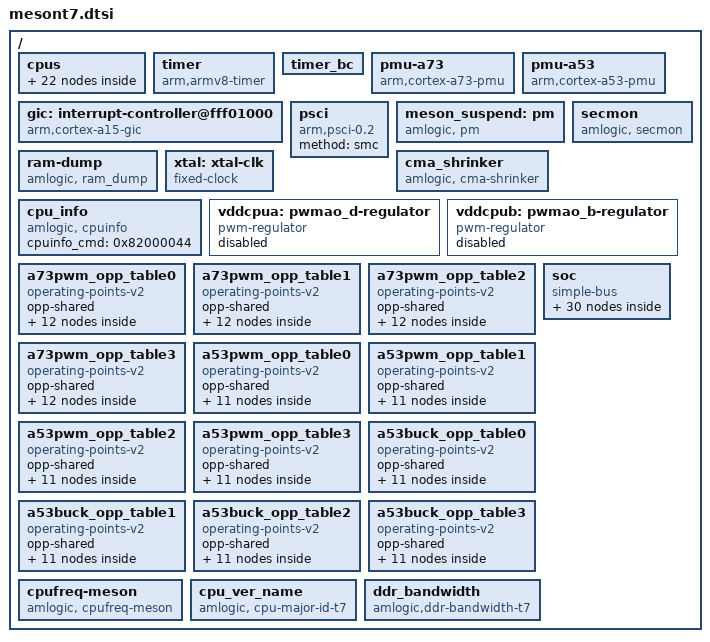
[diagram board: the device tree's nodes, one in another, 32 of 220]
// SPDX-License-Identifier: (GPL-2.0+ OR MIT)
/*
 * Copyright (c) 2019 Amlogic, Inc. All rights reserved.
 */

#include <dt-bindings/clock/amlogic,t7-clkc.h>
#include <dt-bindings/interrupt-controller/arm-gic.h>
#include <dt-bindings/gpio/gpio.h>
#include <dt-bindings/gpio/meson-t7-gpio.h>
#include <dt-bindings/pwm/meson.h>


/ {
	cpus:cpus {
		#address-cells = <2>;
		#size-cells = <0>;

		cpu-map {
			cluster0:cluster0 {
				core0 {
					cpu = <&CPU0>;
				};
				core1 {
					cpu = <&CPU1>;
				};
				core2 {
					cpu = <&CPU2>;
				};
				core3 {
					cpu = <&CPU3>;
				};
			};
			cluster1:cluster1 {
				core0 {
					cpu = <&CPU4>;
				};
				core1 {
					cpu = <&CPU5>;
				};
				core2 {
					cpu = <&CPU6>;
				};
				core3 {
					cpu = <&CPU7>;
				};
			};
		};

		CPU0:cpu@0 {
			device_type = "cpu";
			compatible = "arm,cortex-a73","arm,armv8";
			reg = <0x0 0x0>;
			enable-method = "psci";
			cpu-idle-states = <&CPU_SLEEP_0 &SYSTEM_SLEEP_0>;
//			#cooling-cells = <2>;
			clocks = <&clkc CLKID_A73_CLK>,
				<&clkc CLKID_A73_DYN_CLK>,
				<&clkc CLKID_SYS_PLL>;
			clock-names = "core_clk",
				"low_freq_clk_parent",
				"high_freq_clk_parent";
			voltage-tolerance = <0>;
			clock-latency = <50000>;
			capacity-dmips-mhz = <1024>;
			dynamic-power-coefficient = <550>;
			#cooling-cells = <2>;
		};

		CPU1:cpu@1 {
			device_type = "cpu";
			compatible = "arm,cortex-a73","arm,armv8";
			reg = <0x0 0x1>;
			enable-method = "psci";
			cpu-idle-states = <&CPU_SLEEP_0 &SYSTEM_SLEEP_0>;
//			#cooling-cells = <2>;
			clocks = <&clkc CLKID_A73_CLK>,
				<&clkc CLKID_A73_DYN_CLK>,
				<&clkc CLKID_SYS_PLL>;
			clock-names = "core_clk",
				"low_freq_clk_parent",
				"high_freq_clk_parent";
			voltage-tolerance = <0>;
			clock-latency = <50000>;
			capacity-dmips-mhz = <1024>;
			dynamic-power-coefficient = <550>;
			#cooling-cells = <2>;
		};

		CPU2:cpu@2 {
			device_type = "cpu";
			compatible = "arm,cortex-a73","arm,armv8";
			reg = <0x0 0x2>;
			enable-method = "psci";
			cpu-idle-states = <&CPU_SLEEP_0 &SYSTEM_SLEEP_0>;
//			#cooling-cells = <2>;
			clocks = <&clkc CLKID_A73_CLK>,
				<&clkc CLKID_A73_DYN_CLK>,
				<&clkc CLKID_SYS_PLL>;
			clock-names = "core_clk",
				"low_freq_clk_parent",
				"high_freq_clk_parent";
			voltage-tolerance = <0>;
			clock-latency = <50000>;
			capacity-dmips-mhz = <1024>;
			dynamic-power-coefficient = <550>;
			#cooling-cells = <2>;
		};

		CPU3:cpu@3 {
			device_type = "cpu";
			compatible = "arm,cortex-a73","arm,armv8";
			reg = <0x0 0x3>;
			enable-method = "psci";
			cpu-idle-states = <&CPU_SLEEP_0 &SYSTEM_SLEEP_0>;
//			#cooling-cells = <2>;
			clocks = <&clkc CLKID_A73_CLK>,
				<&clkc CLKID_A73_DYN_CLK>,
				<&clkc CLKID_SYS_PLL>;
			clock-names = "core_clk",
				"low_freq_clk_parent",
				"high_freq_clk_parent";
			voltage-tolerance = <0>;
			clock-latency = <50000>;
			capacity-dmips-mhz = <1024>;
			dynamic-power-coefficient = <550>;
			#cooling-cells = <2>;
		};

		CPU4:cpu@100 {
			device_type = "cpu";
			compatible = "arm,cortex-a53","arm,armv8";
			reg = <0x0 0x100>;
			enable-method = "psci";
			cpu-idle-states = <&CPU_SLEEP_0 &SYSTEM_SLEEP_0>;
//			#cooling-cells = <2>;
			clocks = <&clkc CLKID_CPU_CLK>,
				<&clkc CLKID_CPU_DYN_CLK>,
				<&clkc CLKID_SYS1_PLL>;
			clock-names = "core_clk",
				"low_freq_clk_parent",
				"high_freq_clk_parent";
			voltage-tolerance = <0>;
			clock-latency = <50000>;
			capacity-dmips-mhz = <632>;
			dynamic-power-coefficient = <110>;
			#cooling-cells = <2>;
		};

		CPU5:cpu@101{
			device_type = "cpu";
			compatible = "arm,cortex-a53","arm,armv8";
			reg = <0x0 0x101>;
			enable-method = "psci";
			cpu-idle-states = <&CPU_SLEEP_0 &SYSTEM_SLEEP_0>;
//			#cooling-cells = <2>;
			clocks = <&clkc CLKID_CPU_CLK>,
				<&clkc CLKID_CPU_DYN_CLK>,
				<&clkc CLKID_SYS1_PLL>;
			clock-names = "core_clk",
				"low_freq_clk_parent",
				"high_freq_clk_parent";
			voltage-tolerance = <0>;
			clock-latency = <50000>;
			capacity-dmips-mhz = <632>;
			dynamic-power-coefficient = <110>;
			#cooling-cells = <2>;
		};

		CPU6:cpu@102 {
			device_type = "cpu";
			compatible = "arm,cortex-a53","arm,armv8";
			reg = <0x0 0x102>;
			enable-method = "psci";
			cpu-idle-states = <&CPU_SLEEP_0 &SYSTEM_SLEEP_0>;
//			#cooling-cells = <2>;
			clocks = <&clkc CLKID_CPU_CLK>,
				<&clkc CLKID_CPU_DYN_CLK>,
				<&clkc CLKID_SYS1_PLL>;
			clock-names = "core_clk",
				"low_freq_clk_parent",
				"high_freq_clk_parent";
			voltage-tolerance = <0>;
			clock-latency = <50000>;
			capacity-dmips-mhz = <632>;
			dynamic-power-coefficient = <110>;
			#cooling-cells = <2>;
		};

		CPU7:cpu@103 {
			device_type = "cpu";
			compatible = "arm,cortex-a53","arm,armv8";
			reg = <0x0 0x103>;
			enable-method = "psci";
			cpu-idle-states = <&CPU_SLEEP_0 &SYSTEM_SLEEP_0>;
//			#cooling-cells = <2>;
			clocks = <&clkc CLKID_CPU_CLK>,
				<&clkc CLKID_CPU_DYN_CLK>,
				<&clkc CLKID_SYS1_PLL>;
			clock-names = "core_clk",
				"low_freq_clk_parent",
				"high_freq_clk_parent";
			voltage-tolerance = <0>;
			clock-latency = <50000>;
			capacity-dmips-mhz = <632>;
			dynamic-power-coefficient = <110>;
			#cooling-cells = <2>;
		};

		idle-states {
			entry-method = "arm,psci-0.2";
			CPU_SLEEP_0: cpu-sleep-0 {
					compatible = "arm,idle-state";
					arm,psci-suspend-param = <0x0010000>;
					local-timer-stop;
					entry-latency-us = <4000>;
					exit-latency-us = <5000>;
					min-residency-us = <10000>;
			};
			SYSTEM_SLEEP_0: system-sleep-0 {
					compatible = "arm,idle-state";
					arm,psci-suspend-param = <0x0000000>;
					entry-latency-us = <0x3fffffff>;
					exit-latency-us = <0x40000000>;
					min-residency-us = <0xffffffff>;
			};
		};
	};

	timer {
		compatible = "arm,armv8-timer";
		interrupts = <GIC_PPI 13 0xff08>,
				<GIC_PPI 14 0xff08>,
				<GIC_PPI 11 0xff08>,
				<GIC_PPI 10 0xff08>;
	};

	timer_bc {
		/*compatible = "amlogic,bc-timer";*/
		reg= <0x0 0xfe0100D8 0x0 0x4 0x0 0xfe0100DC 0x0 0x4>;
		timer_name = "Meson TimerD";
		clockevent-rating=<300>;
		clockevent-shift=<20>;
		clockevent-features=<0x23>;
		interrupts = <0 3 1>;
		bit_enable=<7>;
		bit_mode=<6>;
		bit_resolution=<0>;
		resolution_1us=<1>;
		min_delta_ns=<10>;
	};

	pmu-a73 {
		compatible = "arm,cortex-a73-pmu";
		private-interrupts;
		interrupts = <GIC_SPI 265 IRQ_TYPE_LEVEL_HIGH>,
			     <GIC_SPI 266 IRQ_TYPE_LEVEL_HIGH>,
			     <GIC_SPI 267 IRQ_TYPE_LEVEL_HIGH>,
			     <GIC_SPI 268 IRQ_TYPE_LEVEL_HIGH>;
		interrupt-affinity = <&CPU0>,
					<&CPU1>,
					<&CPU2>,
					<&CPU3>;
	};

	pmu-a53 {
		compatible = "arm,cortex-a53-pmu";
		private-interrupts;
		interrupts = <GIC_SPI 233 IRQ_TYPE_LEVEL_HIGH>,
				<GIC_SPI 234 IRQ_TYPE_LEVEL_HIGH>,
				<GIC_SPI 235 IRQ_TYPE_LEVEL_HIGH>,
				<GIC_SPI 236 IRQ_TYPE_LEVEL_HIGH>;
		interrupt-affinity = <&CPU4>,
					<&CPU5>,
					<&CPU6>,
					<&CPU7>;
	};

	gic: interrupt-controller@fff01000 {
		compatible = "arm,cortex-a15-gic", "arm,cortex-a9-gic";
		#interrupt-cells = <3>;
		#address-cells = <0>;
		interrupt-controller;
		reg = <0x0 0xfff01000 0 0x1000>,
		      <0x0 0xfff02000 0 0x0100>;
		interrupts = <GIC_PPI 9 0xf04>;
	};

	psci {
		compatible = "arm,psci-0.2";
		method = "smc";
	};

	meson_suspend:pm {
		compatible = "amlogic, pm";
		status = "okay";
		device_name = "aml_pm";
		reg = <0x0 0xfe010288 0x0 0x4>, /*SYSCTRL_STATUS_REG2*/
			<0x0 0xfe0102dc 0x0 0x4>; /*SYSCTRL_STICKY_REG7*/
	};

	ram-dump {
		compatible = "amlogic, ram_dump";
		status = "okay";
		reg = <0x0 0xFE0102D8 0x0 4>;
		reg-names = "SYSCTRL_STICKY_REG6";
		store_device = "data";
	};

	secmon {
		compatible = "amlogic, secmon";
		memory-region = <&secmon_reserved>;
		in_base_func = <0x82000020>;
		out_base_func = <0x82000021>;
		inout_size_func = <0x8200002a>;
		reserve_mem_size = <0x03300000>;
		clear_range = <0x05100000 0x2a00000>;
	};

	cma_shrinker: cma_shrinker {
		compatible = "amlogic, cma-shrinker";
		status = "okay";
		adj  = <0 100 200 250 900 950>;
		free = <8192 12288 16384 24576 28672 32768>;
	};

	xtal: xtal-clk {
		compatible = "fixed-clock";
		clock-frequency = <24000000>;
		clock-output-names = "xtal";
		#clock-cells = <0>;
	};

	cpu_info {
		compatible = "amlogic, cpuinfo";
		status = "okay";
		cpuinfo_cmd = <0x82000044>;
	};

	vddcpua: pwmao_d-regulator {
		compatible = "pwm-regulator";
		pwms = <&pwmao_cd MESON_PWM_1 1500 0>;
		regulator-name = "vddcpua";
		regulator-min-microvolt = <689000>;
		regulator-max-microvolt = <1049000>;
		regulator-always-on;
		max-duty-cycle = <1500>;
		/* Voltage Duty-Cycle */
		voltage-table = <1049000 0>,
				<1039000 3>,
				<1029000 6>,
				<1019000 9>,
				<1009000 12>,
				<999000 14>,
				<989000 17>,
				<979000 20>,
				<969000 23>,
				<959000 26>,
				<949000 29>,
				<939000 31>,
				<929000 34>,
				<919000 37>,
				<909000 40>,
				<899000 43>,
				<889000 45>,
				<879000 48>,
				<869000 51>,
				<859000 54>,
				<849000 56>,
				<839000 59>,
				<829000 62>,
				<819000 65>,
				<809000 68>,
				<799000 70>,
				<789000 73>,
				<779000 76>,
				<769000 79>,
				<759000 81>,
				<749000 84>,
				<739000 87>,
				<729000 89>,
				<719000 92>,
				<709000 95>,
				<699000 98>,
				<689000 100>;
		status = "disabled";
	};

	vddcpub: pwmao_b-regulator {
		compatible = "pwm-regulator";
		pwms = <&pwmao_ab MESON_PWM_1 1500 0>;
		regulator-name = "vddcpub";
		regulator-min-microvolt = <689000>;
		regulator-max-microvolt = <1049000>;
		regulator-always-on;
		max-duty-cycle = <1500>;
		/* Voltage Duty-Cycle */
		voltage-table = <1049000 0>,
				<1039000 3>,
				<1029000 6>,
				<1019000 9>,
				<1009000 12>,
				<999000 14>,
				<989000 17>,
				<979000 20>,
				<969000 23>,
				<959000 26>,
				<949000 29>,
				<939000 31>,
				<929000 34>,
				<919000 37>,
				<909000 40>,
				<899000 43>,
				<889000 45>,
				<879000 48>,
				<869000 51>,
				<859000 54>,
				<849000 56>,
				<839000 59>,
				<829000 62>,
				<819000 65>,
				<809000 68>,
				<799000 70>,
				<789000 73>,
				<779000 76>,
				<769000 79>,
				<759000 81>,
				<749000 84>,
				<739000 87>,
				<729000 89>,
				<719000 92>,
				<709000 95>,
				<699000 98>,
				<689000 100>;
		status = "disabled";
	};

	a73pwm_opp_table0: a73pwm_opp_table0 {
		compatible = "operating-points-v2";
		opp-shared;

		opp00 {
			opp-hz = /bits/ 64 <500000000>;
			opp-microvolt = <819000>;
		};
		opp01 {
			opp-hz = /bits/ 64 <666000000>;
			opp-microvolt = <819000>;
		};
		opp02 {
			opp-hz = /bits/ 64 <1000000000>;
			opp-microvolt = <819000>;
		};
		opp03 {
			opp-hz = /bits/ 64 <1200000000>;
			opp-microvolt = <819000>;
		};
		opp04 {
			opp-hz = /bits/ 64 <1392000000>;
			opp-microvolt = <819000>;
		};
		opp05 {
			opp-hz = /bits/ 64 <1512000000>;
			opp-microvolt = <829000>;
		};
		opp06 {
			opp-hz = /bits/ 64 <1608000000>;
			opp-microvolt = <849000>;
		};
		opp07 {
			opp-hz = /bits/ 64 <1704000000>;
			opp-microvolt = <869000>;
		};
		opp08 {
			opp-hz = /bits/ 64 <1800000000>;
			opp-microvolt = <909000>;
		};
		opp09 {
			opp-hz = /bits/ 64 <1896000000>;
			opp-microvolt = <939000>;
		};
		opp10 {
			opp-hz = /bits/ 64 <2016000000>;
			opp-microvolt = <959000>;
		};
		opp11 {
			opp-hz = /bits/ 64 <2208000000>;
			opp-microvolt = <1009000>;
		};
	};

	a73pwm_opp_table1: a73pwm_opp_table1 {
		compatible = "operating-points-v2";
		opp-shared;

		opp00 {
			opp-hz = /bits/ 64 <500000000>;
			opp-microvolt = <819000>;
		};
		opp01 {
			opp-hz = /bits/ 64 <666000000>;
			opp-microvolt = <819000>;
		};
		opp02 {
			opp-hz = /bits/ 64 <1000000000>;
			opp-microvolt = <819000>;
		};
		opp03 {
			opp-hz = /bits/ 64 <1200000000>;
			opp-microvolt = <819000>;
		};
		opp04 {
			opp-hz = /bits/ 64 <1392000000>;
			opp-microvolt = <819000>;
		};
		opp05 {
			opp-hz = /bits/ 64 <1512000000>;
			opp-microvolt = <829000>;
		};
		opp06 {
			opp-hz = /bits/ 64 <1608000000>;
			opp-microvolt = <849000>;
		};
		opp07 {
			opp-hz = /bits/ 64 <1704000000>;
			opp-microvolt = <869000>;
		};
		opp08 {
			opp-hz = /bits/ 64 <1800000000>;
			opp-microvolt = <909000>;
		};
		opp09 {
			opp-hz = /bits/ 64 <1896000000>;
			opp-microvolt = <939000>;
		};
		opp10 {
			opp-hz = /bits/ 64 <2016000000>;
			opp-microvolt = <959000>;
		};
		opp11 {
			opp-hz = /bits/ 64 <2208000000>;
			opp-microvolt = <1009000>;
		};
	};

	a73pwm_opp_table2: a73pwm_opp_table2 {
		compatible = "operating-points-v2";
		opp-shared;

		opp00 {
			opp-hz = /bits/ 64 <500000000>;
			opp-microvolt = <799000>;
		};
		opp01 {
			opp-hz = /bits/ 64 <666000000>;
			opp-microvolt = <799000>;
		};
		opp02 {
			opp-hz = /bits/ 64 <1000000000>;
			opp-microvolt = <799000>;
		};
		opp03 {
			opp-hz = /bits/ 64 <1200000000>;
			opp-microvolt = <799000>;
		};
		opp04 {
			opp-hz = /bits/ 64 <1392000000>;
			opp-microvolt = <809000>;
		};
		opp05 {
			opp-hz = /bits/ 64 <1512000000>;
			opp-microvolt = <809000>;
		};
		opp06 {
			opp-hz = /bits/ 64 <1608000000>;
			opp-microvolt = <829000>;
		};
		opp07 {
			opp-hz = /bits/ 64 <1704000000>;
			opp-microvolt = <849000>;
		};
		opp08 {
			opp-hz = /bits/ 64 <1800000000>;
			opp-microvolt = <859000>;
		};
		opp09 {
			opp-hz = /bits/ 64 <1896000000>;
			opp-microvolt = <889000>;
		};
		opp10 {
			opp-hz = /bits/ 64 <2016000000>;
			opp-microvolt = <919000>;
		};
		opp11 {
			opp-hz = /bits/ 64 <2208000000>;
			opp-microvolt = <969000>;
		};
	};

	a73pwm_opp_table3: a73pwm_opp_table3 {
		compatible = "operating-points-v2";
		opp-shared;

		opp00 {
			opp-hz = /bits/ 64 <500000000>;
			opp-microvolt = <789000>;
		};
		opp01 {
			opp-hz = /bits/ 64 <666000000>;
			opp-microvolt = <789000>;
		};
		opp02 {
			opp-hz = /bits/ 64 <1000000000>;
			opp-microvolt = <789000>;
		};
		opp03 {
			opp-hz = /bits/ 64 <1200000000>;
			opp-microvolt = <789000>;
		};
		opp04 {
			opp-hz = /bits/ 64 <1392000000>;
			opp-microvolt = <809000>;
		};
		opp05 {
			opp-hz = /bits/ 64 <1512000000>;
			opp-microvolt = <809000>;
		};
		opp06 {
			opp-hz = /bits/ 64 <1608000000>;
			opp-microvolt = <819000>;
		};
		opp07 {
			opp-hz = /bits/ 64 <1704000000>;
			opp-microvolt = <829000>;
		};
		opp08 {
			opp-hz = /bits/ 64 <1800000000>;
			opp-microvolt = <849000>;
		};
		opp09 {
			opp-hz = /bits/ 64 <1896000000>;
			opp-microvolt = <859000>;
		};
		opp10 {
			opp-hz = /bits/ 64 <2016000000>;
			opp-microvolt = <879000>;
		};
		opp11 {
			opp-hz = /bits/ 64 <2208000000>;
			opp-microvolt = <919000>;
		};
	};

	a53pwm_opp_table0: a53pwm_opp_table0 {
		compatible = "operating-points-v2";
		opp-shared;

		opp00 {
			opp-hz = /bits/ 64 <500000000>;
			opp-microvolt = <769000>;
		};
		opp01 {
			opp-hz = /bits/ 64 <666000000>;
			opp-microvolt = <769000>;
		};
		opp02 {
			opp-hz = /bits/ 64 <1000000000>;
			opp-microvolt = <769000>;
		};
		opp03 {
			opp-hz = /bits/ 64 <1200000000>;
			opp-microvolt = <769000>;
		};
		opp04 {
			opp-hz = /bits/ 64 <1392000000>;
			opp-microvolt = <769000>;
		};
		opp05 {
			opp-hz = /bits/ 64 <1512000000>;
			opp-microvolt = <809000>;
		};
		opp06 {
			opp-hz = /bits/ 64 <1608000000>;
			opp-microvolt = <839000>;
		};
		opp07 {
			opp-hz = /bits/ 64 <1704000000>;
			opp-microvolt = <869000>;
		};
		opp08 {
			opp-hz = /bits/ 64 <1800000000>;
			opp-microvolt = <909000>;
		};
		opp09 {
			opp-hz = /bits/ 64 <1896000000>;
			opp-microvolt = <949000>;
		};
		opp10 {
			opp-hz = /bits/ 64 <2016000000>;
			opp-microvolt = <1009000>;
		};
	};

	a53pwm_opp_table1: a53pwm_opp_table1 {
		compatible = "operating-points-v2";
		opp-shared;

		opp00 {
			opp-hz = /bits/ 64 <500000000>;
			opp-microvolt = <769000>;
		};
		opp01 {
			opp-hz = /bits/ 64 <666000000>;
			opp-microvolt = <769000>;
		};
		opp02 {
			opp-hz = /bits/ 64 <1000000000>;
			opp-microvolt = <769000>;
		};
		opp03 {
			opp-hz = /bits/ 64 <1200000000>;
			opp-microvolt = <769000>;
		};
		opp04 {
			opp-hz = /bits/ 64 <1392000000>;
			opp-microvolt = <769000>;
		};
		opp05 {
			opp-hz = /bits/ 64 <1512000000>;
			opp-microvolt = <809000>;
		};
		opp06 {
			opp-hz = /bits/ 64 <1608000000>;
			opp-microvolt = <839000>;
		};
		opp07 {
			opp-hz = /bits/ 64 <1704000000>;
			opp-microvolt = <869000>;
		};
		opp08 {
			opp-hz = /bits/ 64 <1800000000>;
			opp-microvolt = <909000>;
		};
		opp09 {
			opp-hz = /bits/ 64 <1896000000>;
			opp-microvolt = <949000>;
		};
		opp10 {
			opp-hz = /bits/ 64 <2016000000>;
			opp-microvolt = <1009000>;
		};
	};

	a53pwm_opp_table2: a53pwm_opp_table2 {
		compatible = "operating-points-v2";
		opp-shared;

		opp00 {
			opp-hz = /bits/ 64 <500000000>;
			opp-microvolt = <759000>;
		};
		opp01 {
			opp-hz = /bits/ 64 <666000000>;
			opp-microvolt = <759000>;
		};
		opp02 {
			opp-hz = /bits/ 64 <1000000000>;
			opp-microvolt = <759000>;
		};
		opp03 {
			opp-hz = /bits/ 64 <1200000000>;
			opp-microvolt = <759000>;
		};
		opp04 {
			opp-hz = /bits/ 64 <1392000000>;
			opp-microvolt = <769000>;
		};
		opp05 {
			opp-hz = /bits/ 64 <1512000000>;
			opp-microvolt = <789000>;
		};
		opp06 {
			opp-hz = /bits/ 64 <1608000000>;
			opp-microvolt = <799000>;
		};
		opp07 {
			opp-hz = /bits/ 64 <1704000000>;
			opp-microvolt = <829000>;
		};
		opp08 {
			opp-hz = /bits/ 64 <1800000000>;
			opp-microvolt = <859000>;
		};
		opp09 {
			opp-hz = /bits/ 64 <1896000000>;
			opp-microvolt = <899000>;
		};
		opp10 {
			opp-hz = /bits/ 64 <2016000000>;
			opp-microvolt = <949000>;
		};
	};

	a53pwm_opp_table3: a53pwm_opp_table3 {
		compatible = "operating-points-v2";
		opp-shared;

		opp00 {
			opp-hz = /bits/ 64 <500000000>;
			opp-microvolt = <749000>;
		};
		opp01 {
			opp-hz = /bits/ 64 <666000000>;
			opp-microvolt = <749000>;
		};
		opp02 {
			opp-hz = /bits/ 64 <1000000000>;
			opp-microvolt = <749000>;
		};
		opp03 {
			opp-hz = /bits/ 64 <1200000000>;
			opp-microvolt = <749000>;
		};
		opp04 {
			opp-hz = /bits/ 64 <1392000000>;
			opp-microvolt = <769000>;
		};
		opp05 {
			opp-hz = /bits/ 64 <1512000000>;
			opp-microvolt = <779000>;
		};
		opp06 {
			opp-hz = /bits/ 64 <1608000000>;
			opp-microvolt = <789000>;
		};
		opp07 {
			opp-hz = /bits/ 64 <1704000000>;
			opp-microvolt = <809000>;
		};
		opp08 {
			opp-hz = /bits/ 64 <1800000000>;
			opp-microvolt = <829000>;
		};
		opp09 {
			opp-hz = /bits/ 64 <1896000000>;
			opp-microvolt = <859000>;
		};
		opp10 {
			opp-hz = /bits/ 64 <2016000000>;
			opp-microvolt = <919000>;
		};
	};

	a53buck_opp_table0: a53buck_opp_table0 {
		compatible = "operating-points-v2";
		opp-shared;

		opp00 {
			opp-hz = /bits/ 64 <500000000>;
			opp-microvolt = <770000>;
		};
		opp01 {
			opp-hz = /bits/ 64 <666000000>;
			opp-microvolt = <770000>;
		};
		opp02 {
			opp-hz = /bits/ 64 <1000000000>;
			opp-microvolt = <770000>;
		};
		opp03 {
			opp-hz = /bits/ 64 <1200000000>;
			opp-microvolt = <770000>;
		};
		opp04 {
			opp-hz = /bits/ 64 <1392000000>;
			opp-microvolt = <770000>;
		};
		opp05 {
			opp-hz = /bits/ 64 <1512000000>;
			opp-microvolt = <810000>;
		};
		opp06 {
			opp-hz = /bits/ 64 <1608000000>;
			opp-microvolt = <840000>;
		};
		opp07 {
			opp-hz = /bits/ 64 <1704000000>;
			opp-microvolt = <870000>;
		};
		opp08 {
			opp-hz = /bits/ 64 <1800000000>;
			opp-microvolt = <910000>;
		};
		opp09 {
			opp-hz = /bits/ 64 <1896000000>;
			opp-microvolt = <950000>;
		};
		opp10 {
			opp-hz = /bits/ 64 <2016000000>;
			opp-microvolt = <1010000>;
		};
	};

	a53buck_opp_table1: a53buck_opp_table1 {
		compatible = "operating-points-v2";
		opp-shared;

		opp00 {
			opp-hz = /bits/ 64 <500000000>;
			opp-microvolt = <770000>;
		};
		opp01 {
			opp-hz = /bits/ 64 <666000000>;
			opp-microvolt = <770000>;
		};
		opp02 {
			opp-hz = /bits/ 64 <1000000000>;
			opp-microvolt = <770000>;
		};
		opp03 {
			opp-hz = /bits/ 64 <1200000000>;
			opp-microvolt = <770000>;
		};
		opp04 {
			opp-hz = /bits/ 64 <1392000000>;
			opp-microvolt = <770000>;
		};
		opp05 {
			opp-hz = /bits/ 64 <1512000000>;
			opp-microvolt = <810000>;
		};
		opp06 {
			opp-hz = /bits/ 64 <1608000000>;
			opp-microvolt = <840000>;
		};
		opp07 {
			opp-hz = /bits/ 64 <1704000000>;
			opp-microvolt = <870000>;
		};
		opp08 {
			opp-hz = /bits/ 64 <1800000000>;
			opp-microvolt = <910000>;
		};
		opp09 {
			opp-hz = /bits/ 64 <1896000000>;
			opp-microvolt = <950000>;
		};
		opp10 {
			opp-hz = /bits/ 64 <2016000000>;
			opp-microvolt = <1010000>;
		};
	};

	a53buck_opp_table2: a53buck_opp_table2 {
		compatible = "operating-points-v2";
		opp-shared;

		opp00 {
			opp-hz = /bits/ 64 <500000000>;
			opp-microvolt = <760000>;
		};
		opp01 {
			opp-hz = /bits/ 64 <666000000>;
			opp-microvolt = <760000>;
		};
		opp02 {
			opp-hz = /bits/ 64 <1000000000>;
			opp-microvolt = <760000>;
		};
		opp03 {
			opp-hz = /bits/ 64 <1200000000>;
			opp-microvolt = <760000>;
		};
		opp04 {
			opp-hz = /bits/ 64 <1392000000>;
			opp-microvolt = <770000>;
		};
		opp05 {
			opp-hz = /bits/ 64 <1512000000>;
			opp-microvolt = <790000>;
		};
		opp06 {
			opp-hz = /bits/ 64 <1608000000>;
			opp-microvolt = <800000>;
		};
		opp07 {
			opp-hz = /bits/ 64 <1704000000>;
			opp-microvolt = <830000>;
		};
		opp08 {
			opp-hz = /bits/ 64 <1800000000>;
			opp-microvolt = <860000>;
		};
		opp09 {
			opp-hz = /bits/ 64 <1896000000>;
			opp-microvolt = <900000>;
		};
		opp10 {
			opp-hz = /bits/ 64 <2016000000>;
			opp-microvolt = <950000>;
		};
	};

	a53buck_opp_table3: a53buck_opp_table3 {
		compatible = "operating-points-v2";
		opp-shared;

		opp00 {
			opp-hz = /bits/ 64 <500000000>;
			opp-microvolt = <750000>;
		};
		opp01 {
			opp-hz = /bits/ 64 <666000000>;
			opp-microvolt = <750000>;
		};
		opp02 {
			opp-hz = /bits/ 64 <1000000000>;
			opp-microvolt = <750000>;
		};
		opp03 {
			opp-hz = /bits/ 64 <1200000000>;
			opp-microvolt = <750000>;
		};
		opp04 {
			opp-hz = /bits/ 64 <1392000000>;
			opp-microvolt = <770000>;
		};
		opp05 {
			opp-hz = /bits/ 64 <1512000000>;
			opp-microvolt = <780000>;
		};
		opp06 {
			opp-hz = /bits/ 64 <1608000000>;
			opp-microvolt = <790000>;
		};
		opp07 {
			opp-hz = /bits/ 64 <1704000000>;
			opp-microvolt = <810000>;
		};
		opp08 {
			opp-hz = /bits/ 64 <1800000000>;
			opp-microvolt = <830000>;
		};
		opp09 {
			opp-hz = /bits/ 64 <1896000000>;
			opp-microvolt = <860000>;
		};
		opp10 {
			opp-hz = /bits/ 64 <2016000000>;
			opp-microvolt = <920000>;
		};
	};

	cpufreq-meson {
		compatible = "amlogic, cpufreq-meson";
		status = "okay";
	};

	soc {
		compatible = "simple-bus";
		#address-cells = <2>;
		#size-cells = <2>;
		ranges;

		apb4: apb4@fe000000 {
			compatible = "simple-bus";
			reg = <0x0 0xfe000000 0x0 0x480000>;
			#address-cells = <2>;
			#size-cells = <2>;
			ranges = <0x0 0x0 0x0 0xfe000000 0x0 0x480000>;

			clkc: clock-controller {
				compatible = "amlogic,t7-clkc";
				#clock-cells = <1>;
				reg = <0x0 0x0 0x0 0x49c>,
				      <0x0 0x8000 0x0 0x320>,
				      <0x0 0xe040 0x0 0xbc>;
				reg-names = "basic", "pll",
					    "cpu_clk";
				clocks = <&xtal>;
				clock-names = "xtal";
				status = "okay";
			};

			meson_clk_msr@48000 {
				compatible = "amlogic,meson-t7-clk-measure";
				reg = <0x0 0x48000 0x0 0x1c>;
			};

			periphs_pinctrl: pinctrl@4000 {
				compatible = "amlogic,meson-t7-periphs-pinctrl";
				#address-cells = <2>;
				#size-cells = <2>;
				ranges;

				gpio: bank@4000 {
					reg = <0x0 0x4000 0x0 0x0064>,
					      <0x0 0x40c0 0x0 0x0220>;
					reg-names = "mux", "gpio";
					gpio-controller;
					#gpio-cells = <2>;
					gpio-ranges = <&periphs_pinctrl 0 0 157>;
				};
			};

			gpio_intc: interrupt-controller@4080 {
				compatible = "amlogic,meson-t7-gpio-intc",
					     "amlogic,meson-gpio-intc";
				reg = <0x0 0x4080 0x0 0x20>;
				interrupt-controller;
				#interrupt-cells = <2>;
				amlogic,channel-interrupts =
					<10 11 12 13 14 15 16 17 18 19 20 21>;
			};

			pwmao_ab: pwm@5e000 {
				compatible = "amlogic,meson-v2-pwm";
				reg = <0x0 0x5e000 0x0 0x24>;
				#pwm-cells = <3>;
				clocks = <&clkc CLKID_PWM_AO_A_GATE>,
						<&clkc CLKID_PWM_AO_B_GATE>;
				clock-names = "clkin0", "clkin1";
				status = "disabled";
			};

			pwmao_cd: pwm@60000 {
				compatible = "amlogic,meson-v2-pwm";
				reg = <0x0 0x60000 0x0 0x24>;
				#pwm-cells = <3>;
				clocks = <&clkc CLKID_PWM_AO_C_GATE>,
						<&clkc CLKID_PWM_AO_D_GATE>;
				clock-names = "clkin0", "clkin1";
				status = "disabled";
			};

			reset: reset-controller@2000 {
				compatible = "amlogic,meson-t7-reset";
				reg = <0x0 0x2000 0x0 0x98>;
				#reset-cells = <1>;
			};

			cpu_version {
				compatible = "amlogic,meson-gx-ao-secure", "syscon";
				reg=<0x0 0x10220 0x0 0x140>;
				amlogic,has-chip-id;
			};
		};

		sd_emmc_b: sd@fe08a000 {
			compatible = "amlogic,meson-axg-mmc";
			reg = <0x0 0xfe08a000 0x0 0x800>,
				<0x0 0xfe00016c 0x0 0x4>,
				<0x0 0xfe00401c 0x0 0x4>;
			interrupts = <GIC_SPI 177 IRQ_TYPE_EDGE_RISING>;
			status = "disabled";
			clocks = <&clkc CLKID_SD_EMMC_B>,
				<&clkc CLKID_SD_EMMC_B_CLK_MUX>,
				 <&clkc CLKID_SD_EMMC_B_CLK>,
				 <&xtal>,
				 <&clkc CLKID_FCLK_DIV2>;
			clock-names = "core", "mux0", "mux1",
					"clkin0", "clkin1";
			card_type = <5>;
			use_intf3_tuning;
			mmc_debug_flag;
			//resets = <&reset RESET_SD_EMMC_B>;
		};

		uart_A: serial@fe078000 {
			compatible = "amlogic,meson-t7-uart";
			reg = <0x0 0xfe078000 0x0 0x18>;
			interrupts = <0 168 1>;
			status = "disabled";
			clocks = <&xtal>, <&clkc CLKID_UART_A>, <&xtal>;
			clock-names = "xtal", "pclk", "baud";
			fifo-size = < 64 >;
			pinctrl-names = "default";
		};
	};

	cpu_ver_name {
		compatible = "amlogic, cpu-major-id-t7";
	};

	ddr_bandwidth {
		compatible = "amlogic,ddr-bandwidth-t7";
		status = "okay";
		reg = <0 0xfe036000 0 0x400
		       0 0xfe034000 0 0x400
		       0 0xfe0a0000 0 0x100>;
		interrupts = <0 332 IRQ_TYPE_EDGE_RISING
			      0 336 IRQ_TYPE_EDGE_RISING>;
		interrupt-names = "ddr_bandwidth";
	};
};

&periphs_pinctrl {
	/* sdemmc portB */
	sd_clk_cmd_pins:sd_clk_cmd_pins {
		mux {
			groups = "sdcard_cmd";
			function = "sdcard";
			bias-pull-up;
			drive-strength-microamp = <4000>;
		};
		mux1 {
			groups = "sdcard_clk";
			function = "sdcard";
			bias-pull-up;
			drive-strength-microamp = <4000>;
		};
	};

	sd_all_pins:sd_all_pins {
		mux {
			groups = "sdcard_d0",
				   "sdcard_d1",
				   "sdcard_d2",
				   "sdcard_d3",
				   "sdcard_cmd";
			function = "sdcard";
			bias-pull-up;
			drive-strength-microamp = <4000>;
		};
		mux1 {
			groups = "sdcard_clk";
			function = "sdcard";
			bias-pull-up;
			drive-strength-microamp = <4000>;
		};
	};

	sd_clk_gate_pins: sd_clk_gate {
		mux {
			groups = "GPIOC_4";
			function = "gpio_periphs";
			bias-pull-down;
			drive-strength-microamp = <4000>;
		};
	};

	sd_all_pd_pins:sd_all_pd_pins {
		mux {
			groups = "GPIOC_0",
				   "GPIOC_1",
				   "GPIOC_2",
				   "GPIOC_3",
				   "GPIOC_4",
				   "GPIOC_5";
			function = "gpio_periphs";
			bias-pull-down;
			output-low;
		};
	};

	sd_1bit_pins:sd_1bit_pins {
		mux {
			groups = "sdcard_d0",
					"sdcard_cmd";
			function = "sdcard";
			bias-pull-up;
			drive-strength-microamp = <4000>;
		};
		mux1 {
			groups = "sdcard_clk";
			function = "sdcard";
			bias-pull-up;
			drive-strength-microamp = <4000>;
		};
	};

	sd_clr_all_pins:sd_clr_all_pins {
		mux {
			groups = "GPIOC_0",
				   "GPIOC_1",
				   "GPIOC_2",
				   "GPIOC_3",
				   "GPIOC_5";
			function = "gpio_periphs";
			output-high;
		};
		mux1 {
			groups = "GPIOC_4";
			function = "gpio_periphs";
			output-low;
		};
	};

	sd_clr_noall_pins:sd_clr_noall_pins {
		mux {
			groups = "GPIOC_0",
				   "GPIOC_1",
				   "GPIOC_4",
				   "GPIOC_5";
			function = "gpio_periphs";
			output-high;
		};
	};
};

